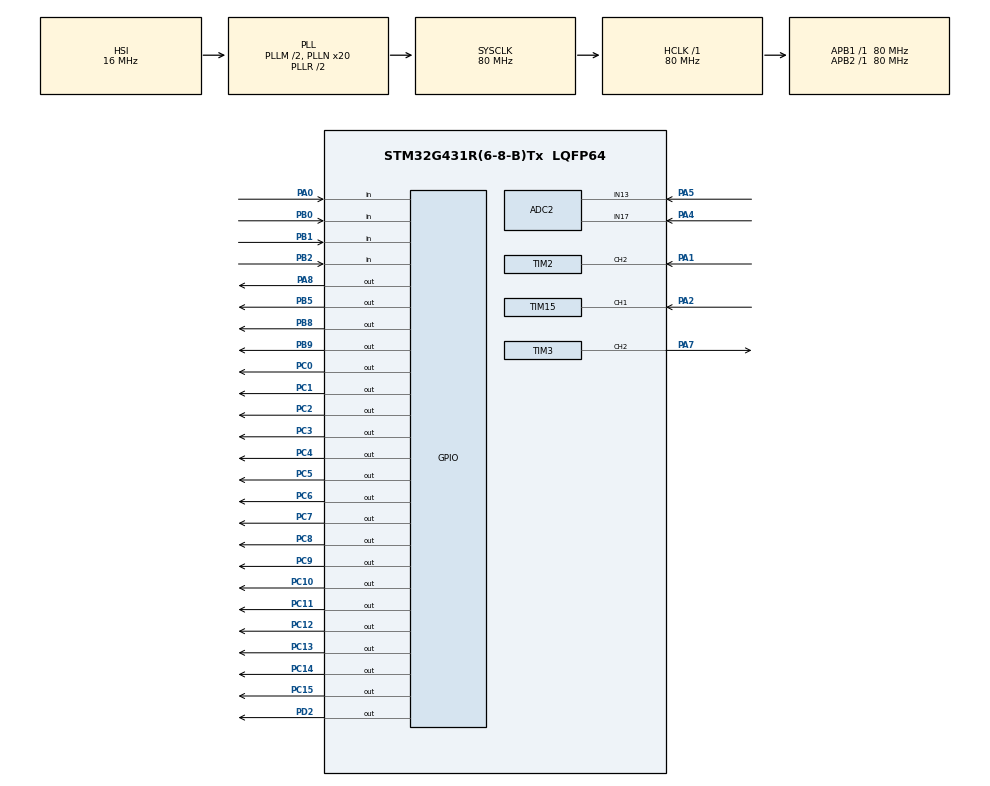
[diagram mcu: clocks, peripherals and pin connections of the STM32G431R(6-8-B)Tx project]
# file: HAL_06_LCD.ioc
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ADC2.Channel-0\#ChannelRegularConversion=ADC_CHANNEL_17
ADC2.Channel-1\#ChannelRegularConversion=ADC_CHANNEL_13
ADC2.ContinuousConvMode=ENABLE
ADC2.DMAContinuousRequests=ENABLE
ADC2.NbrOfConversion=2
ADC2.NbrOfConversionFlag=1
ADC2.OffsetNumber-0\#ChannelRegularConversion=ADC_OFFSET_NONE
ADC2.OffsetNumber-1\#ChannelRegularConversion=ADC_OFFSET_NONE
ADC2.Rank-0\#ChannelRegularConversion=1
ADC2.Rank-1\#ChannelRegularConversion=2
ADC2.SamplingTime-0\#ChannelRegularConversion=ADC_SAMPLETIME_640CYCLES_5
ADC2.SamplingTime-1\#ChannelRegularConversion=ADC_SAMPLETIME_640CYCLES_5
Dma.ADC2.0.Direction=DMA_PERIPH_TO_MEMORY
Dma.ADC2.0.EventEnable=DISABLE
Dma.ADC2.0.Instance=DMA1_Channel1
Dma.ADC2.0.MemDataAlignment=DMA_MDATAALIGN_HALFWORD
Dma.ADC2.0.MemInc=DMA_MINC_ENABLE
Dma.ADC2.0.Mode=DMA_CIRCULAR
Dma.ADC2.0.PeriphDataAlignment=DMA_PDATAALIGN_HALFWORD
Dma.ADC2.0.PeriphInc=DMA_PINC_DISABLE
Dma.ADC2.0.Polarity=HAL_DMAMUX_REQ_GEN_RISING
Dma.ADC2.0.Priority=DMA_PRIORITY_LOW
Dma.ADC2.0.RequestNumber=1
Dma.ADC2.0.SignalID=NONE
Dma.ADC2.0.SyncEnable=DISABLE
Dma.ADC2.0.SyncPolarity=HAL_DMAMUX_SYNC_NO_EVENT
Dma.ADC2.0.SyncRequestNumber=1
Dma.ADC2.0.SyncSignalID=NONE
Dma.Request0=ADC2
Mcu.Family=STM32G4
Mcu.Name=STM32G431R(6-8-B)Tx
Mcu.Package=LQFP64
NVIC.DMA1_Channel1_IRQn=true\:0\:0\:false\:false\:true\:false\:true\:true
NVIC.PriorityGroup=NVIC_PRIORITYGROUP_4
NVIC.TIM6_DAC_IRQn=true\:0\:0\:false\:false\:true\:true\:true\:true
PA0.GPIO_PuPd=GPIO_PULLUP
PA0.Signal=GPIO_Input
PA1.Signal=S_TIM2_CH2
PA13.Mode=Serial_Wire
PA13.Signal=SYS_JTMS-SWDIO
PA14.Mode=Serial_Wire
PA14.Signal=SYS_JTCK-SWCLK
PA2.Signal=S_TIM15_CH1
PA4.Mode=IN17-Single-Ended
PA4.Signal=ADC2_IN17
PA5.Mode=IN13-Single-Ended
PA5.Signal=ADC2_IN13
PA7.Signal=S_TIM3_CH2
PA8.Signal=GPIO_Output
PB0.GPIO_PuPd=GPIO_PULLUP
PB0.Signal=GPIO_Input
PB1.GPIO_PuPd=GPIO_PULLUP
PB1.Signal=GPIO_Input
PB2.GPIO_PuPd=GPIO_PULLUP
PB2.Signal=GPIO_Input
PB5.Signal=GPIO_Output
PB8-BOOT0.Signal=GPIO_Output
PB9.Signal=GPIO_Output
PC0.Signal=GPIO_Output
PC1.Signal=GPIO_Output
PC10.GPIO_ModeDefaultOutputPP=GPIO_MODE_OUTPUT_PP
PC10.GPIO_PuPd=GPIO_PULLUP
PC10.PinState=GPIO_PIN_SET
PC10.Signal=GPIO_Output
PC11.GPIO_ModeDefaultOutputPP=GPIO_MODE_OUTPUT_PP
PC11.GPIO_PuPd=GPIO_PULLUP
PC11.PinState=GPIO_PIN_SET
PC11.Signal=GPIO_Output
PC12.GPIO_ModeDefaultOutputPP=GPIO_MODE_OUTPUT_PP
PC12.GPIO_PuPd=GPIO_PULLUP
PC12.PinState=GPIO_PIN_SET
PC12.Signal=GPIO_Output
PC13.GPIO_ModeDefaultOutputPP=GPIO_MODE_OUTPUT_PP
PC13.GPIO_PuPd=GPIO_PULLUP
PC13.PinState=GPIO_PIN_SET
PC13.Signal=GPIO_Output
PC14-OSC32_IN.GPIO_ModeDefaultOutputPP=GPIO_MODE_OUTPUT_PP
PC14-OSC32_IN.GPIO_PuPd=GPIO_PULLUP
PC14-OSC32_IN.PinState=GPIO_PIN_SET
PC14-OSC32_IN.Signal=GPIO_Output
PC15-OSC32_OUT.GPIO_ModeDefaultOutputPP=GPIO_MODE_OUTPUT_PP
PC15-OSC32_OUT.GPIO_PuPd=GPIO_PULLUP
PC15-OSC32_OUT.PinState=GPIO_PIN_SET
PC15-OSC32_OUT.Signal=GPIO_Output
PC2.Signal=GPIO_Output
PC3.Signal=GPIO_Output
PC4.Signal=GPIO_Output
PC5.Signal=GPIO_Output
PC6.Signal=GPIO_Output
PC7.Signal=GPIO_Output
PC8.GPIO_ModeDefaultOutputPP=GPIO_MODE_OUTPUT_PP
PC8.GPIO_PuPd=GPIO_PULLUP
PC8.PinState=GPIO_PIN_SET
PC8.Signal=GPIO_Output
PC9.GPIO_ModeDefaultOutputPP=GPIO_MODE_OUTPUT_PP
PC9.GPIO_PuPd=GPIO_PULLUP
PC9.PinState=GPIO_PIN_SET
PC9.Signal=GPIO_Output
PD2.Signal=GPIO_Output
PF0-OSC_IN.Mode=HSE-External-Oscillator
PF0-OSC_IN.Signal=RCC_OSC_IN
PF1-OSC_OUT.Mode=HSE-External-Oscillator
PF1-OSC_OUT.Signal=RCC_OSC_OUT
ProjectManager.HeapSize=0x200
ProjectManager.StackSize=0x400
ProjectManager.TargetToolchain=MDK-ARM V5.27
RCC.ADC12Freq_Value=80000000
RCC.AHBFreq_Value=80000000
RCC.APB1Freq_Value=80000000
RCC.APB1TimFreq_Value=80000000
RCC.APB2Freq_Value=80000000
RCC.APB2TimFreq_Value=80000000
RCC.CortexFreq_Value=80000000
RCC.EXTERNAL_CLOCK_VALUE=12288000
RCC.HCLKFreq_Value=80000000
RCC.HSE_VALUE=24000000
RCC.HSI48_VALUE=48000000
RCC.HSI_VALUE=16000000
RCC.LSE_VALUE=32768
RCC.PLLM=RCC_PLLM_DIV2
RCC.PLLN=20
RCC.SYSCLKFreq_VALUE=80000000
RCC.SYSCLKSource=RCC_SYSCLKSOURCE_PLLCLK
RCC.USBFreq_Value=80000000
RCC.VCOOutputFreq_Value=160000000
SH.S_TIM15_CH1.0=TIM15_CH1,TriggerSource_TI1FP1
SH.S_TIM15_CH1.1=TIM15_CH1,Input_Capture1_from_TI1
SH.S_TIM2_CH2.0=TIM2_CH2,TriggerSource_TI2FP2
SH.S_TIM2_CH2.1=TIM2_CH2,Input_Capture2_from_TI2
SH.S_TIM3_CH2.0=TIM3_CH2,PWM Generation2 CH2
TIM15.Channel-Input_Capture1_from_TI1=TIM_CHANNEL_1
TIM15.Channel-Input_Capture2_from_TI1_63=TIM_CHANNEL_2
TIM15.ICPolarity_CH2=TIM_INPUTCHANNELPOLARITY_FALLING
TIM15.Prescaler=80-1
TIM2.Channel-Input_Capture1_from_TI2_63=TIM_CHANNEL_1
TIM2.Channel-Input_Capture2_from_TI2=TIM_CHANNEL_2
TIM2.ICPolarity_CH1=TIM_INPUTCHANNELPOLARITY_FALLING
TIM2.Prescaler=80-1
TIM3.Channel-PWM\ Generation2\ CH2=TIM_CHANNEL_2
TIM3.PeriodNoDither=10000-1
TIM3.Prescaler=8-1
TIM3.PulseNoDither_2=5000
TIM6.PeriodNoDither=10000-1
TIM6.Prescaler=80-1
VP_SYS_VS_DBSignals.Mode=DisableDeadBatterySignals
VP_TIM15_VS_ClockSourceINT.Mode=Internal
VP_TIM15_VS_ControllerModeReset.Mode=Reset Mode
VP_TIM15_VS_indirect_ch1.Mode=Input_Capture2_from_TI1_63
VP_TIM2_VS_ClockSourceINT.Mode=Internal
VP_TIM2_VS_ControllerModeReset.Mode=Reset Mode
VP_TIM2_VS_indirect_ch2.Mode=Input_Capture1_from_TI2_63
VP_TIM3_VS_ClockSourceINT.Mode=Internal
VP_TIM6_VS_ClockSourceINT.Mode=Enable_Timer
board=custom

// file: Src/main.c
/* USER CODE BEGIN Header */
/**
  ******************************************************************************
  * @file           : main.c
  * @brief          : Main program body
  ******************************************************************************
  * @attention
  *
  * <h2><center>&copy; Copyright (c) 2021 STMicroelectronics.
  * All rights reserved.</center></h2>
  *
  * This software component is licensed by ST under BSD 3-Clause license,
  * the "License"; You may not use this file except in compliance with the
  * License. You may obtain a copy of the License at:
  *                        opensource.org/licenses/BSD-3-Clause
  *
  ******************************************************************************
  */
/* USER CODE END Header */
#include "main.h"
#include "adc.h"
#include "dma.h"
#include "tim.h"
#include "gpio.h"

/* USER CODE BEGIN Includes */
#include "my_main.h"
/* USER CODE END Includes */

void SystemClock_Config(void);

int main(void)
{

  /* MCU Configuration--------------------------------------------------------*/

  /* Reset of all peripherals, Initializes the Flash interface and the Systick. */
  HAL_Init();

  /* Configure the system clock */
  SystemClock_Config();

  /* Initialize all configured peripherals */
  MX_GPIO_Init();
  MX_DMA_Init();
  MX_TIM6_Init();
  MX_ADC2_Init();
  MX_TIM2_Init();
  MX_TIM15_Init();
  MX_TIM3_Init();
  /* USER CODE BEGIN 2 */

  setup();
  /* USER CODE END 2 */

  /* Infinite loop */
  /* USER CODE BEGIN WHILE */

    while (1)
    {
			loop();
    /* USER CODE END WHILE */

    }
}

void SystemClock_Config(void)
{
  RCC_OscInitTypeDef RCC_OscInitStruct = {0};
  RCC_ClkInitTypeDef RCC_ClkInitStruct = {0};

  /** Configure the main internal regulator output voltage
  */
  HAL_PWREx_ControlVoltageScaling(PWR_REGULATOR_VOLTAGE_SCALE1);

  /** Initializes the RCC Oscillators according to the specified parameters
  * in the RCC_OscInitTypeDef structure.
  */
  RCC_OscInitStruct.OscillatorType = RCC_OSCILLATORTYPE_HSI;
  RCC_OscInitStruct.HSIState = RCC_HSI_ON;
  RCC_OscInitStruct.HSICalibrationValue = RCC_HSICALIBRATION_DEFAULT;
  RCC_OscInitStruct.PLL.PLLState = RCC_PLL_ON;
  RCC_OscInitStruct.PLL.PLLSource = RCC_PLLSOURCE_HSI;
  RCC_OscInitStruct.PLL.PLLM = RCC_PLLM_DIV2;
  RCC_OscInitStruct.PLL.PLLN = 20;
  RCC_OscInitStruct.PLL.PLLP = RCC_PLLP_DIV2;
  RCC_OscInitStruct.PLL.PLLQ = RCC_PLLQ_DIV2;
  RCC_OscInitStruct.PLL.PLLR = RCC_PLLR_DIV2;
  if (HAL_RCC_OscConfig(&RCC_OscInitStruct) != HAL_OK)
  {
    Error_Handler();
  }

  /** Initializes the CPU, AHB and APB buses clocks
  */
  RCC_ClkInitStruct.ClockType = RCC_CLOCKTYPE_HCLK|RCC_CLOCKTYPE_SYSCLK
                              |RCC_CLOCKTYPE_PCLK1|RCC_CLOCKTYPE_PCLK2;
  RCC_ClkInitStruct.SYSCLKSource = RCC_SYSCLKSOURCE_PLLCLK;
  RCC_ClkInitStruct.AHBCLKDivider = RCC_SYSCLK_DIV1;
  RCC_ClkInitStruct.APB1CLKDivider = RCC_HCLK_DIV1;
  RCC_ClkInitStruct.APB2CLKDivider = RCC_HCLK_DIV1;

  if (HAL_RCC_ClockConfig(&RCC_ClkInitStruct, FLASH_LATENCY_2) != HAL_OK)
  {
    Error_Handler();
  }
}

void Error_Handler(void)
{
}
